AUTOSAR XML (schema 4-0-3)
standard types defined: Boolean, UInt16, UInt8
package /AUTOSAR_Platform/DataConstrs
  range DC_Boolean: raw 0..1
  range DC_UInt16: raw 0..65535
  range DC_UInt8: raw 0..255
package /PATAC/MSM/ComponentTypes
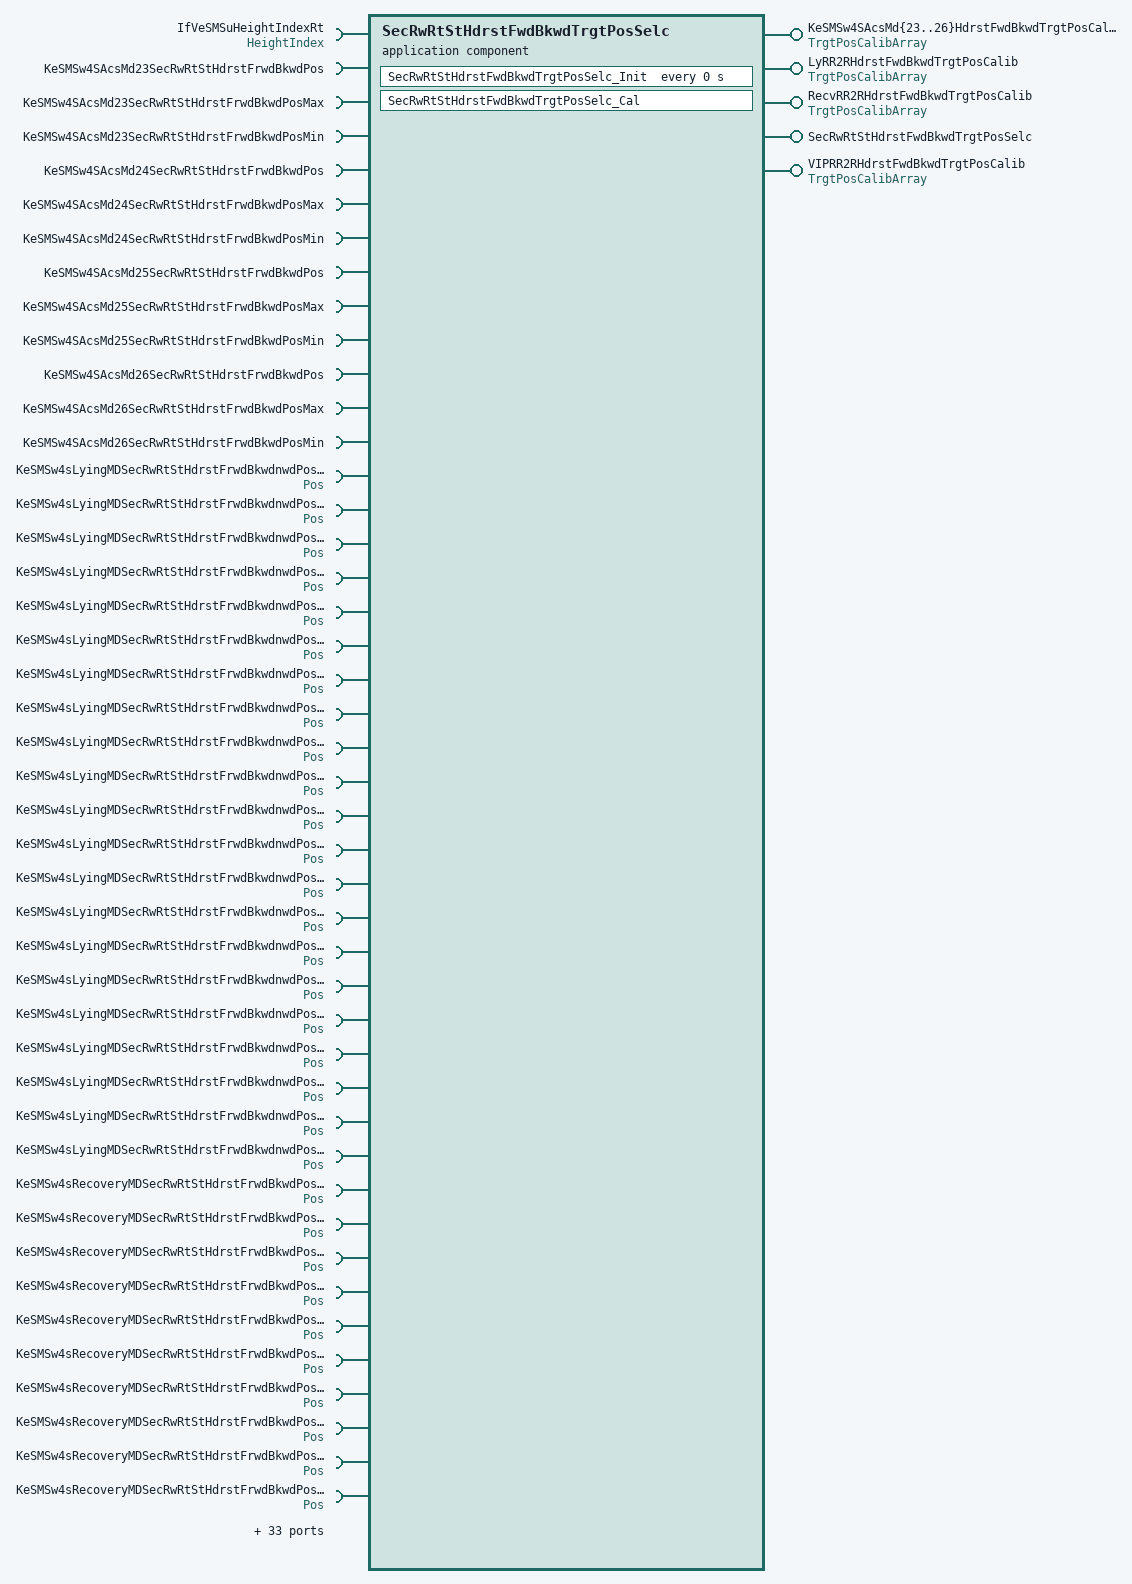
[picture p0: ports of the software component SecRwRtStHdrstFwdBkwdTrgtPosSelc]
  application sw component type SecRwRtStHdrstFwdBkwdTrgtPosSelc
    8 x provide port:
      KeSMSw4SAcsMd{23..26}HdrstFwdBkwdTrgtPosCalib: nonqueued-sender-com-spec{data-element=TrgtPosArray, init-value=[4095, 4095, 4095]}, provided-interface=TrgtPosCalibArray
      LyRR2RHdrstFwdBkwdTrgtPosCalib: nonqueued-sender-com-spec{data-element=TrgtPosArray, init-value=[4095, 4095, 4095]}, provided-interface=TrgtPosCalibArray
      RecvRR2RHdrstFwdBkwdTrgtPosCalib: nonqueued-sender-com-spec{data-element=TrgtPosArray, init-value=[4095, 4095, 4095]}, provided-interface=TrgtPosCalibArray
      SecRwRtStHdrstFwdBkwdTrgtPosSelc: server-com-spec{operation=Cal, queue-length=1}, provided-interface=SecRwRtStHdrstFwdBkwdTrgtPosSelc
      VIPRR2RHdrstFwdBkwdTrgtPosCalib: nonqueued-sender-com-spec{data-element=TrgtPosArray, init-value=[4095, 4095, 4095]}, provided-interface=TrgtPosCalibArray
    77 x require port:
      IfVeSMSuHeightIndexRt: nonqueued-receiver-com-spec{data-element=Val, filter=data-filter-type=ALWAYS, init-value=0}, required-interface=HeightIndex
      KeSMSw4SAcsMd23SecRwRtStHdrstFrwdBkwdPos: parameter-require-com-spec{init-value=0, parameter=KeSMSw4SAcsMd23SecRwRtStHdrstFrwdBkwdPos/Val}, required-interface=KeSMSw4SAcsMd23SecRwRtStHdrstFrwdBkwdPos
      KeSMSw4SAcsMd23SecRwRtStHdrstFrwdBkwdPosMax: parameter-require-com-spec{init-value=0, parameter=KeSMSw4SAcsMd23SecRwRtStHdrstFrwdBkwdPosMax/Val}, required-interface=KeSMSw4SAcsMd23SecRwRtStHdrstFrwdBkwdPosMax
      KeSMSw4SAcsMd23SecRwRtStHdrstFrwdBkwdPosMin: parameter-require-com-spec{init-value=0, parameter=KeSMSw4SAcsMd23SecRwRtStHdrstFrwdBkwdPosMin/Val}, required-interface=KeSMSw4SAcsMd23SecRwRtStHdrstFrwdBkwdPosMin
      KeSMSw4SAcsMd24SecRwRtStHdrstFrwdBkwdPos: parameter-require-com-spec{init-value=0, parameter=KeSMSw4SAcsMd24SecRwRtStHdrstFrwdBkwdPos/Val}, required-interface=KeSMSw4SAcsMd24SecRwRtStHdrstFrwdBkwdPos
      KeSMSw4SAcsMd24SecRwRtStHdrstFrwdBkwdPosMax: parameter-require-com-spec{init-value=0, parameter=KeSMSw4SAcsMd24SecRwRtStHdrstFrwdBkwdPosMax/Val}, required-interface=KeSMSw4SAcsMd24SecRwRtStHdrstFrwdBkwdPosMax
      KeSMSw4SAcsMd24SecRwRtStHdrstFrwdBkwdPosMin: parameter-require-com-spec{init-value=0, parameter=KeSMSw4SAcsMd24SecRwRtStHdrstFrwdBkwdPosMin/Val}, required-interface=KeSMSw4SAcsMd24SecRwRtStHdrstFrwdBkwdPosMin
      KeSMSw4SAcsMd25SecRwRtStHdrstFrwdBkwdPos: parameter-require-com-spec{init-value=0, parameter=KeSMSw4SAcsMd25SecRwRtStHdrstFrwdBkwdPos/Val}, required-interface=KeSMSw4SAcsMd25SecRwRtStHdrstFrwdBkwdPos
      KeSMSw4SAcsMd25SecRwRtStHdrstFrwdBkwdPosMax: parameter-require-com-spec{init-value=0, parameter=KeSMSw4SAcsMd25SecRwRtStHdrstFrwdBkwdPosMax/Val}, required-interface=KeSMSw4SAcsMd25SecRwRtStHdrstFrwdBkwdPosMax
      KeSMSw4SAcsMd25SecRwRtStHdrstFrwdBkwdPosMin: parameter-require-com-spec{init-value=0, parameter=KeSMSw4SAcsMd25SecRwRtStHdrstFrwdBkwdPosMin/Val}, required-interface=KeSMSw4SAcsMd25SecRwRtStHdrstFrwdBkwdPosMin
      KeSMSw4SAcsMd26SecRwRtStHdrstFrwdBkwdPos: parameter-require-com-spec{init-value=0, parameter=KeSMSw4SAcsMd26SecRwRtStHdrstFrwdBkwdPos/Val}, required-interface=KeSMSw4SAcsMd26SecRwRtStHdrstFrwdBkwdPos
      KeSMSw4SAcsMd26SecRwRtStHdrstFrwdBkwdPosMax: parameter-require-com-spec{init-value=0, parameter=KeSMSw4SAcsMd26SecRwRtStHdrstFrwdBkwdPosMax/Val}, required-interface=KeSMSw4SAcsMd26SecRwRtStHdrstFrwdBkwdPosMax
      KeSMSw4SAcsMd26SecRwRtStHdrstFrwdBkwdPosMin: parameter-require-com-spec{init-value=0, parameter=KeSMSw4SAcsMd26SecRwRtStHdrstFrwdBkwdPosMin/Val}, required-interface=KeSMSw4SAcsMd26SecRwRtStHdrstFrwdBkwdPosMin
      KeSMSw4sLyingMDSecRwRtStHdrstFrwdBkwdnwdPos_160: parameter-require-com-spec{init-value=0, parameter=Pos/Val}, required-interface=Pos
      KeSMSw4sLyingMDSecRwRtStHdrstFrwdBkwdnwdPos_165: parameter-require-com-spec{init-value=0, parameter=Pos/Val}, required-interface=Pos
      KeSMSw4sLyingMDSecRwRtStHdrstFrwdBkwdnwdPos_170: parameter-require-com-spec{init-value=0, parameter=Pos/Val}, required-interface=Pos
      KeSMSw4sLyingMDSecRwRtStHdrstFrwdBkwdnwdPos_175: parameter-require-com-spec{init-value=0, parameter=Pos/Val}, required-interface=Pos
      KeSMSw4sLyingMDSecRwRtStHdrstFrwdBkwdnwdPos_180: parameter-require-com-spec{init-value=0, parameter=Pos/Val}, required-interface=Pos
      KeSMSw4sLyingMDSecRwRtStHdrstFrwdBkwdnwdPos_Below160: parameter-require-com-spec{init-value=0, parameter=Pos/Val}, required-interface=Pos
      KeSMSw4sLyingMDSecRwRtStHdrstFrwdBkwdnwdPos_Over180: parameter-require-com-spec{init-value=0, parameter=Pos/Val}, required-interface=Pos
      KeSMSw4sLyingMDSecRwRtStHdrstFrwdBkwdnwdPosMax_160: parameter-require-com-spec{init-value=0, parameter=Pos/Val}, required-interface=Pos
      KeSMSw4sLyingMDSecRwRtStHdrstFrwdBkwdnwdPosMax_165: parameter-require-com-spec{init-value=0, parameter=Pos/Val}, required-interface=Pos
      KeSMSw4sLyingMDSecRwRtStHdrstFrwdBkwdnwdPosMax_170: parameter-require-com-spec{init-value=0, parameter=Pos/Val}, required-interface=Pos
      KeSMSw4sLyingMDSecRwRtStHdrstFrwdBkwdnwdPosMax_175: parameter-require-com-spec{init-value=0, parameter=Pos/Val}, required-interface=Pos
      KeSMSw4sLyingMDSecRwRtStHdrstFrwdBkwdnwdPosMax_180: parameter-require-com-spec{init-value=0, parameter=Pos/Val}, required-interface=Pos
      KeSMSw4sLyingMDSecRwRtStHdrstFrwdBkwdnwdPosMax_Below160: parameter-require-com-spec{init-value=0, parameter=Pos/Val}, required-interface=Pos
      KeSMSw4sLyingMDSecRwRtStHdrstFrwdBkwdnwdPosMax_Over180: parameter-require-com-spec{init-value=0, parameter=Pos/Val}, required-interface=Pos
      KeSMSw4sLyingMDSecRwRtStHdrstFrwdBkwdnwdPosMin_160: parameter-require-com-spec{init-value=0, parameter=Pos/Val}, required-interface=Pos
      KeSMSw4sLyingMDSecRwRtStHdrstFrwdBkwdnwdPosMin_165: parameter-require-com-spec{init-value=0, parameter=Pos/Val}, required-interface=Pos
      KeSMSw4sLyingMDSecRwRtStHdrstFrwdBkwdnwdPosMin_170: parameter-require-com-spec{init-value=0, parameter=Pos/Val}, required-interface=Pos
      KeSMSw4sLyingMDSecRwRtStHdrstFrwdBkwdnwdPosMin_175: parameter-require-com-spec{init-value=0, parameter=Pos/Val}, required-interface=Pos
      KeSMSw4sLyingMDSecRwRtStHdrstFrwdBkwdnwdPosMin_180: parameter-require-com-spec{init-value=0, parameter=Pos/Val}, required-interface=Pos
      KeSMSw4sLyingMDSecRwRtStHdrstFrwdBkwdnwdPosMin_Below160: parameter-require-com-spec{init-value=0, parameter=Pos/Val}, required-interface=Pos
      KeSMSw4sLyingMDSecRwRtStHdrstFrwdBkwdnwdPosMin_Over180: parameter-require-com-spec{init-value=0, parameter=Pos/Val}, required-interface=Pos
      KeSMSw4sRecoveryMDSecRwRtStHdrstFrwdBkwdPos_160: parameter-require-com-spec{init-value=0, parameter=Pos/Val}, required-interface=Pos
      KeSMSw4sRecoveryMDSecRwRtStHdrstFrwdBkwdPos_165: parameter-require-com-spec{init-value=0, parameter=Pos/Val}, required-interface=Pos
      KeSMSw4sRecoveryMDSecRwRtStHdrstFrwdBkwdPos_170: parameter-require-com-spec{init-value=0, parameter=Pos/Val}, required-interface=Pos
      KeSMSw4sRecoveryMDSecRwRtStHdrstFrwdBkwdPos_175: parameter-require-com-spec{init-value=0, parameter=Pos/Val}, required-interface=Pos
      KeSMSw4sRecoveryMDSecRwRtStHdrstFrwdBkwdPos_180: parameter-require-com-spec{init-value=0, parameter=Pos/Val}, required-interface=Pos
      KeSMSw4sRecoveryMDSecRwRtStHdrstFrwdBkwdPos_Below160: parameter-require-com-spec{init-value=0, parameter=Pos/Val}, required-interface=Pos
      KeSMSw4sRecoveryMDSecRwRtStHdrstFrwdBkwdPos_Over180: parameter-require-com-spec{init-value=0, parameter=Pos/Val}, required-interface=Pos
      KeSMSw4sRecoveryMDSecRwRtStHdrstFrwdBkwdPosMax_160: parameter-require-com-spec{init-value=0, parameter=Pos/Val}, required-interface=Pos
      KeSMSw4sRecoveryMDSecRwRtStHdrstFrwdBkwdPosMax_165: parameter-require-com-spec{init-value=0, parameter=Pos/Val}, required-interface=Pos
      KeSMSw4sRecoveryMDSecRwRtStHdrstFrwdBkwdPosMax_170: parameter-require-com-spec{init-value=0, parameter=Pos/Val}, required-interface=Pos
      KeSMSw4sRecoveryMDSecRwRtStHdrstFrwdBkwdPosMax_175: parameter-require-com-spec{init-value=0, parameter=Pos/Val}, required-interface=Pos
      KeSMSw4sRecoveryMDSecRwRtStHdrstFrwdBkwdPosMax_180: parameter-require-com-spec{init-value=0, parameter=Pos/Val}, required-interface=Pos
      KeSMSw4sRecoveryMDSecRwRtStHdrstFrwdBkwdPosMax_Below160: parameter-require-com-spec{init-value=0, parameter=Pos/Val}, required-interface=Pos
      KeSMSw4sRecoveryMDSecRwRtStHdrstFrwdBkwdPosMax_Over180: parameter-require-com-spec{init-value=0, parameter=Pos/Val}, required-interface=Pos
      KeSMSw4sRecoveryMDSecRwRtStHdrstFrwdBkwdPosMin_160: parameter-require-com-spec{init-value=0, parameter=Pos/Val}, required-interface=Pos
      KeSMSw4sRecoveryMDSecRwRtStHdrstFrwdBkwdPosMin_165: parameter-require-com-spec{init-value=0, parameter=Pos/Val}, required-interface=Pos
      KeSMSw4sRecoveryMDSecRwRtStHdrstFrwdBkwdPosMin_170: parameter-require-com-spec{init-value=0, parameter=Pos/Val}, required-interface=Pos
      KeSMSw4sRecoveryMDSecRwRtStHdrstFrwdBkwdPosMin_175: parameter-require-com-spec{init-value=0, parameter=Pos/Val}, required-interface=Pos
      KeSMSw4sRecoveryMDSecRwRtStHdrstFrwdBkwdPosMin_180: parameter-require-com-spec{init-value=0, parameter=Pos/Val}, required-interface=Pos
      KeSMSw4sRecoveryMDSecRwRtStHdrstFrwdBkwdPosMin_Below160: parameter-require-com-spec{init-value=0, parameter=Pos/Val}, required-interface=Pos
      KeSMSw4sRecoveryMDSecRwRtStHdrstFrwdBkwdPosMin_Over180: parameter-require-com-spec{init-value=0, parameter=Pos/Val}, required-interface=Pos
      KeSMSw4sVIPMDSecRwRtStHdrstFrwdBkwdPos_160: parameter-require-com-spec{init-value=0, parameter=Pos/Val}, required-interface=Pos
      KeSMSw4sVIPMDSecRwRtStHdrstFrwdBkwdPos_165: parameter-require-com-spec{init-value=0, parameter=Pos/Val}, required-interface=Pos
      KeSMSw4sVIPMDSecRwRtStHdrstFrwdBkwdPos_170: parameter-require-com-spec{init-value=0, parameter=Pos/Val}, required-interface=Pos
      KeSMSw4sVIPMDSecRwRtStHdrstFrwdBkwdPos_175: parameter-require-com-spec{init-value=0, parameter=Pos/Val}, required-interface=Pos
      KeSMSw4sVIPMDSecRwRtStHdrstFrwdBkwdPos_180: parameter-require-com-spec{init-value=0, parameter=Pos/Val}, required-interface=Pos
      KeSMSw4sVIPMDSecRwRtStHdrstFrwdBkwdPos_Below160: parameter-require-com-spec{init-value=0, parameter=Pos/Val}, required-interface=Pos
      KeSMSw4sVIPMDSecRwRtStHdrstFrwdBkwdPos_Over180: parameter-require-com-spec{init-value=0, parameter=Pos/Val}, required-interface=Pos
      KeSMSw4sVIPMDSecRwRtStHdrstFrwdBkwdPosMax_160: parameter-require-com-spec{init-value=0, parameter=Pos/Val}, required-interface=Pos
      KeSMSw4sVIPMDSecRwRtStHdrstFrwdBkwdPosMax_165: parameter-require-com-spec{init-value=0, parameter=Pos/Val}, required-interface=Pos
      KeSMSw4sVIPMDSecRwRtStHdrstFrwdBkwdPosMax_170: parameter-require-com-spec{init-value=0, parameter=Pos/Val}, required-interface=Pos
      KeSMSw4sVIPMDSecRwRtStHdrstFrwdBkwdPosMax_175: parameter-require-com-spec{init-value=0, parameter=Pos/Val}, required-interface=Pos
      KeSMSw4sVIPMDSecRwRtStHdrstFrwdBkwdPosMax_180: parameter-require-com-spec{init-value=0, parameter=Pos/Val}, required-interface=Pos
      KeSMSw4sVIPMDSecRwRtStHdrstFrwdBkwdPosMax_Below160: parameter-require-com-spec{init-value=0, parameter=Pos/Val}, required-interface=Pos
      KeSMSw4sVIPMDSecRwRtStHdrstFrwdBkwdPosMax_Over180: parameter-require-com-spec{init-value=0, parameter=Pos/Val}, required-interface=Pos
      KeSMSw4sVIPMDSecRwRtStHdrstFrwdBkwdPosMin_160: parameter-require-com-spec{init-value=0, parameter=Pos/Val}, required-interface=Pos
      KeSMSw4sVIPMDSecRwRtStHdrstFrwdBkwdPosMin_165: parameter-require-com-spec{init-value=0, parameter=Pos/Val}, required-interface=Pos
      KeSMSw4sVIPMDSecRwRtStHdrstFrwdBkwdPosMin_170: parameter-require-com-spec{init-value=0, parameter=Pos/Val}, required-interface=Pos
      KeSMSw4sVIPMDSecRwRtStHdrstFrwdBkwdPosMin_175: parameter-require-com-spec{init-value=0, parameter=Pos/Val}, required-interface=Pos
      KeSMSw4sVIPMDSecRwRtStHdrstFrwdBkwdPosMin_180: parameter-require-com-spec{init-value=0, parameter=Pos/Val}, required-interface=Pos
      KeSMSw4sVIPMDSecRwRtStHdrstFrwdBkwdPosMin_Below160: parameter-require-com-spec{init-value=0, parameter=Pos/Val}, required-interface=Pos
      KeSMSw4sVIPMDSecRwRtStHdrstFrwdBkwdPosMin_Over180: parameter-require-com-spec{init-value=0, parameter=Pos/Val}, required-interface=Pos
      StNumFlg: required-interface=StNumFlg
        required-com-specs:
          data-element=Is4s, filter=data-filter-type=ALWAYS, init-value=0
          data-element=Is6s, filter=data-filter-type=ALWAYS, init-value=0
          data-element=Is6s7s, filter=data-filter-type=ALWAYS, init-value=0
          data-element=Is7s, filter=data-filter-type=ALWAYS, init-value=0
    behavior SecRwRtStHdrstFwdBkwdTrgtPosSelc_InternalBehavior
      operation invoked event OIT_SecRwRtStHdrstFwdBkwdTrgtPosSelc_Cal_SecRwRtStHdrstFwdBkwdTrgtPosSelc_Cal: start-on-event=SecRwRtStHdrstFwdBkwdTrgtPosSelc_Cal, operation=SecRwRtStHdrstFwdBkwdTrgtPosSelc.Cal
      timing event SecRwRtStHdrstFwdBkwdTrgtPosSelc_InitEvent: start-on-event=SecRwRtStHdrstFwdBkwdTrgtPosSelc_Init, period=0
      runnable SecRwRtStHdrstFwdBkwdTrgtPosSelc_Cal
        data-receive-point-by-arguments:
          5 x access:
            REC_IfVeSMSuHeightIndexRt_Val: accessed-variable=IfVeSMSuHeightIndexRt.Val
            REC_StNumFlg_Is4s: accessed-variable=StNumFlg.Is4s
            REC_StNumFlg_Is6s: accessed-variable=StNumFlg.Is6s
            REC_StNumFlg_Is6s7s: accessed-variable=StNumFlg.Is6s7s
            REC_StNumFlg_Is7s: accessed-variable=StNumFlg.Is7s
        data-send-points:
          7 x access:
            SEND_KeSMSw4SAcsMd{23..26}HdrstFwdBkwdTrgtPosCalib_TrgtPosArray: accessed-variable=KeSMSw4SAcsMd{23..26}HdrstFwdBkwdTrgtPosCalib.TrgtPosArray
            SEND_LyRR2RHdrstFwdBkwdTrgtPosCalib_TrgtPosArray: accessed-variable=LyRR2RHdrstFwdBkwdTrgtPosCalib.TrgtPosArray
            SEND_RecvRR2RHdrstFwdBkwdTrgtPosCalib_TrgtPosArray: accessed-variable=RecvRR2RHdrstFwdBkwdTrgtPosCalib.TrgtPosArray
            SEND_VIPRR2RHdrstFwdBkwdTrgtPosCalib_TrgtPosArray: accessed-variable=VIPRR2RHdrstFwdBkwdTrgtPosCalib.TrgtPosArray
        75 x parameter access:
          PA_KeSMSw4SAcsMd23SecRwRtStHdrstFrwdBkwdPos_Val: accessed-parameter=KeSMSw4SAcsMd23SecRwRtStHdrstFrwdBkwdPos.Val
          PA_KeSMSw4SAcsMd23SecRwRtStHdrstFrwdBkwdPosMax_Val: accessed-parameter=KeSMSw4SAcsMd23SecRwRtStHdrstFrwdBkwdPosMax.Val
          PA_KeSMSw4SAcsMd23SecRwRtStHdrstFrwdBkwdPosMin_Val: accessed-parameter=KeSMSw4SAcsMd23SecRwRtStHdrstFrwdBkwdPosMin.Val
          PA_KeSMSw4SAcsMd24SecRwRtStHdrstFrwdBkwdPos_Val: accessed-parameter=KeSMSw4SAcsMd24SecRwRtStHdrstFrwdBkwdPos.Val
          PA_KeSMSw4SAcsMd24SecRwRtStHdrstFrwdBkwdPosMax_Val: accessed-parameter=KeSMSw4SAcsMd24SecRwRtStHdrstFrwdBkwdPosMax.Val
          PA_KeSMSw4SAcsMd24SecRwRtStHdrstFrwdBkwdPosMin_Val: accessed-parameter=KeSMSw4SAcsMd24SecRwRtStHdrstFrwdBkwdPosMin.Val
          PA_KeSMSw4SAcsMd25SecRwRtStHdrstFrwdBkwdPos_Val: accessed-parameter=KeSMSw4SAcsMd25SecRwRtStHdrstFrwdBkwdPos.Val
          PA_KeSMSw4SAcsMd25SecRwRtStHdrstFrwdBkwdPosMax_Val: accessed-parameter=KeSMSw4SAcsMd25SecRwRtStHdrstFrwdBkwdPosMax.Val
          PA_KeSMSw4SAcsMd25SecRwRtStHdrstFrwdBkwdPosMin_Val: accessed-parameter=KeSMSw4SAcsMd25SecRwRtStHdrstFrwdBkwdPosMin.Val
          PA_KeSMSw4SAcsMd26SecRwRtStHdrstFrwdBkwdPos_Val: accessed-parameter=KeSMSw4SAcsMd26SecRwRtStHdrstFrwdBkwdPos.Val
          PA_KeSMSw4SAcsMd26SecRwRtStHdrstFrwdBkwdPosMax_Val: accessed-parameter=KeSMSw4SAcsMd26SecRwRtStHdrstFrwdBkwdPosMax.Val
          PA_KeSMSw4SAcsMd26SecRwRtStHdrstFrwdBkwdPosMin_Val: accessed-parameter=KeSMSw4SAcsMd26SecRwRtStHdrstFrwdBkwdPosMin.Val
          PA_KeSMSw4sLyingMDSecRwRtStHdrstFrwdBkwdnwdPos_160_Val: accessed-parameter=KeSMSw4sLyingMDSecRwRtStHdrstFrwdBkwdnwdPos_160.Val
          PA_KeSMSw4sLyingMDSecRwRtStHdrstFrwdBkwdnwdPos_165_Val: accessed-parameter=KeSMSw4sLyingMDSecRwRtStHdrstFrwdBkwdnwdPos_165.Val
          PA_KeSMSw4sLyingMDSecRwRtStHdrstFrwdBkwdnwdPos_170_Val: accessed-parameter=KeSMSw4sLyingMDSecRwRtStHdrstFrwdBkwdnwdPos_170.Val
          PA_KeSMSw4sLyingMDSecRwRtStHdrstFrwdBkwdnwdPos_175_Val: accessed-parameter=KeSMSw4sLyingMDSecRwRtStHdrstFrwdBkwdnwdPos_175.Val
          PA_KeSMSw4sLyingMDSecRwRtStHdrstFrwdBkwdnwdPos_180_Val: accessed-parameter=KeSMSw4sLyingMDSecRwRtStHdrstFrwdBkwdnwdPos_180.Val
          PA_KeSMSw4sLyingMDSecRwRtStHdrstFrwdBkwdnwdPos_Below160_Val: accessed-parameter=KeSMSw4sLyingMDSecRwRtStHdrstFrwdBkwdnwdPos_Below160.Val
          PA_KeSMSw4sLyingMDSecRwRtStHdrstFrwdBkwdnwdPos_Over180_Val: accessed-parameter=KeSMSw4sLyingMDSecRwRtStHdrstFrwdBkwdnwdPos_Over180.Val
          PA_KeSMSw4sLyingMDSecRwRtStHdrstFrwdBkwdnwdPosMax_160_Val: accessed-parameter=KeSMSw4sLyingMDSecRwRtStHdrstFrwdBkwdnwdPosMax_160.Val
          PA_KeSMSw4sLyingMDSecRwRtStHdrstFrwdBkwdnwdPosMax_165_Val: accessed-parameter=KeSMSw4sLyingMDSecRwRtStHdrstFrwdBkwdnwdPosMax_165.Val
          PA_KeSMSw4sLyingMDSecRwRtStHdrstFrwdBkwdnwdPosMax_170_Val: accessed-parameter=KeSMSw4sLyingMDSecRwRtStHdrstFrwdBkwdnwdPosMax_170.Val
          PA_KeSMSw4sLyingMDSecRwRtStHdrstFrwdBkwdnwdPosMax_175_Val: accessed-parameter=KeSMSw4sLyingMDSecRwRtStHdrstFrwdBkwdnwdPosMax_175.Val
          PA_KeSMSw4sLyingMDSecRwRtStHdrstFrwdBkwdnwdPosMax_180_Val: accessed-parameter=KeSMSw4sLyingMDSecRwRtStHdrstFrwdBkwdnwdPosMax_180.Val
          PA_KeSMSw4sLyingMDSecRwRtStHdrstFrwdBkwdnwdPosMax_Below160_Val: accessed-parameter=KeSMSw4sLyingMDSecRwRtStHdrstFrwdBkwdnwdPosMax_Below160.Val
          PA_KeSMSw4sLyingMDSecRwRtStHdrstFrwdBkwdnwdPosMax_Over180_Val: accessed-parameter=KeSMSw4sLyingMDSecRwRtStHdrstFrwdBkwdnwdPosMax_Over180.Val
          PA_KeSMSw4sLyingMDSecRwRtStHdrstFrwdBkwdnwdPosMin_160_Val: accessed-parameter=KeSMSw4sLyingMDSecRwRtStHdrstFrwdBkwdnwdPosMin_160.Val
          PA_KeSMSw4sLyingMDSecRwRtStHdrstFrwdBkwdnwdPosMin_165_Val: accessed-parameter=KeSMSw4sLyingMDSecRwRtStHdrstFrwdBkwdnwdPosMin_165.Val
          PA_KeSMSw4sLyingMDSecRwRtStHdrstFrwdBkwdnwdPosMin_170_Val: accessed-parameter=KeSMSw4sLyingMDSecRwRtStHdrstFrwdBkwdnwdPosMin_170.Val
          PA_KeSMSw4sLyingMDSecRwRtStHdrstFrwdBkwdnwdPosMin_175_Val: accessed-parameter=KeSMSw4sLyingMDSecRwRtStHdrstFrwdBkwdnwdPosMin_175.Val
          PA_KeSMSw4sLyingMDSecRwRtStHdrstFrwdBkwdnwdPosMin_180_Val: accessed-parameter=KeSMSw4sLyingMDSecRwRtStHdrstFrwdBkwdnwdPosMin_180.Val
          PA_KeSMSw4sLyingMDSecRwRtStHdrstFrwdBkwdnwdPosMin_Below160_Val: accessed-parameter=KeSMSw4sLyingMDSecRwRtStHdrstFrwdBkwdnwdPosMin_Below160.Val
          PA_KeSMSw4sLyingMDSecRwRtStHdrstFrwdBkwdnwdPosMin_Over180_Val: accessed-parameter=KeSMSw4sLyingMDSecRwRtStHdrstFrwdBkwdnwdPosMin_Over180.Val
          PA_KeSMSw4sRecoveryMDSecRwRtStHdrstFrwdBkwdPos_160_Val: accessed-parameter=KeSMSw4sRecoveryMDSecRwRtStHdrstFrwdBkwdPos_160.Val
          PA_KeSMSw4sRecoveryMDSecRwRtStHdrstFrwdBkwdPos_165_Val: accessed-parameter=KeSMSw4sRecoveryMDSecRwRtStHdrstFrwdBkwdPos_165.Val
          PA_KeSMSw4sRecoveryMDSecRwRtStHdrstFrwdBkwdPos_170_Val: accessed-parameter=KeSMSw4sRecoveryMDSecRwRtStHdrstFrwdBkwdPos_170.Val
          PA_KeSMSw4sRecoveryMDSecRwRtStHdrstFrwdBkwdPos_175_Val: accessed-parameter=KeSMSw4sRecoveryMDSecRwRtStHdrstFrwdBkwdPos_175.Val
          PA_KeSMSw4sRecoveryMDSecRwRtStHdrstFrwdBkwdPos_180_Val: accessed-parameter=KeSMSw4sRecoveryMDSecRwRtStHdrstFrwdBkwdPos_180.Val
          PA_KeSMSw4sRecoveryMDSecRwRtStHdrstFrwdBkwdPos_Below160_Val: accessed-parameter=KeSMSw4sRecoveryMDSecRwRtStHdrstFrwdBkwdPos_Below160.Val
          PA_KeSMSw4sRecoveryMDSecRwRtStHdrstFrwdBkwdPos_Over180_Val: accessed-parameter=KeSMSw4sRecoveryMDSecRwRtStHdrstFrwdBkwdPos_Over180.Val
          PA_KeSMSw4sRecoveryMDSecRwRtStHdrstFrwdBkwdPosMax_160_Val: accessed-parameter=KeSMSw4sRecoveryMDSecRwRtStHdrstFrwdBkwdPosMax_160.Val
          PA_KeSMSw4sRecoveryMDSecRwRtStHdrstFrwdBkwdPosMax_165_Val: accessed-parameter=KeSMSw4sRecoveryMDSecRwRtStHdrstFrwdBkwdPosMax_165.Val
          PA_KeSMSw4sRecoveryMDSecRwRtStHdrstFrwdBkwdPosMax_170_Val: accessed-parameter=KeSMSw4sRecoveryMDSecRwRtStHdrstFrwdBkwdPosMax_170.Val
          PA_KeSMSw4sRecoveryMDSecRwRtStHdrstFrwdBkwdPosMax_175_Val: accessed-parameter=KeSMSw4sRecoveryMDSecRwRtStHdrstFrwdBkwdPosMax_175.Val
          PA_KeSMSw4sRecoveryMDSecRwRtStHdrstFrwdBkwdPosMax_180_Val: accessed-parameter=KeSMSw4sRecoveryMDSecRwRtStHdrstFrwdBkwdPosMax_180.Val
          PA_KeSMSw4sRecoveryMDSecRwRtStHdrstFrwdBkwdPosMax_Below160_Val: accessed-parameter=KeSMSw4sRecoveryMDSecRwRtStHdrstFrwdBkwdPosMax_Below160.Val
          PA_KeSMSw4sRecoveryMDSecRwRtStHdrstFrwdBkwdPosMax_Over180_Val: accessed-parameter=KeSMSw4sRecoveryMDSecRwRtStHdrstFrwdBkwdPosMax_Over180.Val
          PA_KeSMSw4sRecoveryMDSecRwRtStHdrstFrwdBkwdPosMin_160_Val: accessed-parameter=KeSMSw4sRecoveryMDSecRwRtStHdrstFrwdBkwdPosMin_160.Val
          PA_KeSMSw4sRecoveryMDSecRwRtStHdrstFrwdBkwdPosMin_165_Val: accessed-parameter=KeSMSw4sRecoveryMDSecRwRtStHdrstFrwdBkwdPosMin_165.Val
          PA_KeSMSw4sRecoveryMDSecRwRtStHdrstFrwdBkwdPosMin_170_Val: accessed-parameter=KeSMSw4sRecoveryMDSecRwRtStHdrstFrwdBkwdPosMin_170.Val
          PA_KeSMSw4sRecoveryMDSecRwRtStHdrstFrwdBkwdPosMin_175_Val: accessed-parameter=KeSMSw4sRecoveryMDSecRwRtStHdrstFrwdBkwdPosMin_175.Val
          PA_KeSMSw4sRecoveryMDSecRwRtStHdrstFrwdBkwdPosMin_180_Val: accessed-parameter=KeSMSw4sRecoveryMDSecRwRtStHdrstFrwdBkwdPosMin_180.Val
          PA_KeSMSw4sRecoveryMDSecRwRtStHdrstFrwdBkwdPosMin_Below160_Val: accessed-parameter=KeSMSw4sRecoveryMDSecRwRtStHdrstFrwdBkwdPosMin_Below160.Val
          PA_KeSMSw4sRecoveryMDSecRwRtStHdrstFrwdBkwdPosMin_Over180_Val: accessed-parameter=KeSMSw4sRecoveryMDSecRwRtStHdrstFrwdBkwdPosMin_Over180.Val
          PA_KeSMSw4sVIPMDSecRwRtStHdrstFrwdBkwdPos_160_Val: accessed-parameter=KeSMSw4sVIPMDSecRwRtStHdrstFrwdBkwdPos_160.Val
          PA_KeSMSw4sVIPMDSecRwRtStHdrstFrwdBkwdPos_165_Val: accessed-parameter=KeSMSw4sVIPMDSecRwRtStHdrstFrwdBkwdPos_165.Val
          PA_KeSMSw4sVIPMDSecRwRtStHdrstFrwdBkwdPos_170_Val: accessed-parameter=KeSMSw4sVIPMDSecRwRtStHdrstFrwdBkwdPos_170.Val
          PA_KeSMSw4sVIPMDSecRwRtStHdrstFrwdBkwdPos_175_Val: accessed-parameter=KeSMSw4sVIPMDSecRwRtStHdrstFrwdBkwdPos_175.Val
          PA_KeSMSw4sVIPMDSecRwRtStHdrstFrwdBkwdPos_180_Val: accessed-parameter=KeSMSw4sVIPMDSecRwRtStHdrstFrwdBkwdPos_180.Val
          PA_KeSMSw4sVIPMDSecRwRtStHdrstFrwdBkwdPos_Below160_Val: accessed-parameter=KeSMSw4sVIPMDSecRwRtStHdrstFrwdBkwdPos_Below160.Val
          PA_KeSMSw4sVIPMDSecRwRtStHdrstFrwdBkwdPos_Over180_Val: accessed-parameter=KeSMSw4sVIPMDSecRwRtStHdrstFrwdBkwdPos_Over180.Val
          PA_KeSMSw4sVIPMDSecRwRtStHdrstFrwdBkwdPosMax_160_Val: accessed-parameter=KeSMSw4sVIPMDSecRwRtStHdrstFrwdBkwdPosMax_160.Val
          PA_KeSMSw4sVIPMDSecRwRtStHdrstFrwdBkwdPosMax_165_Val: accessed-parameter=KeSMSw4sVIPMDSecRwRtStHdrstFrwdBkwdPosMax_165.Val
          PA_KeSMSw4sVIPMDSecRwRtStHdrstFrwdBkwdPosMax_170_Val: accessed-parameter=KeSMSw4sVIPMDSecRwRtStHdrstFrwdBkwdPosMax_170.Val
          PA_KeSMSw4sVIPMDSecRwRtStHdrstFrwdBkwdPosMax_175_Val: accessed-parameter=KeSMSw4sVIPMDSecRwRtStHdrstFrwdBkwdPosMax_175.Val
          PA_KeSMSw4sVIPMDSecRwRtStHdrstFrwdBkwdPosMax_180_Val: accessed-parameter=KeSMSw4sVIPMDSecRwRtStHdrstFrwdBkwdPosMax_180.Val
          PA_KeSMSw4sVIPMDSecRwRtStHdrstFrwdBkwdPosMax_Below160_Val: accessed-parameter=KeSMSw4sVIPMDSecRwRtStHdrstFrwdBkwdPosMax_Below160.Val
          PA_KeSMSw4sVIPMDSecRwRtStHdrstFrwdBkwdPosMax_Over180_Val: accessed-parameter=KeSMSw4sVIPMDSecRwRtStHdrstFrwdBkwdPosMax_Over180.Val
          PA_KeSMSw4sVIPMDSecRwRtStHdrstFrwdBkwdPosMin_160_Val: accessed-parameter=KeSMSw4sVIPMDSecRwRtStHdrstFrwdBkwdPosMin_160.Val
          PA_KeSMSw4sVIPMDSecRwRtStHdrstFrwdBkwdPosMin_165_Val: accessed-parameter=KeSMSw4sVIPMDSecRwRtStHdrstFrwdBkwdPosMin_165.Val
          PA_KeSMSw4sVIPMDSecRwRtStHdrstFrwdBkwdPosMin_170_Val: accessed-parameter=KeSMSw4sVIPMDSecRwRtStHdrstFrwdBkwdPosMin_170.Val
          PA_KeSMSw4sVIPMDSecRwRtStHdrstFrwdBkwdPosMin_175_Val: accessed-parameter=KeSMSw4sVIPMDSecRwRtStHdrstFrwdBkwdPosMin_175.Val
          PA_KeSMSw4sVIPMDSecRwRtStHdrstFrwdBkwdPosMin_180_Val: accessed-parameter=KeSMSw4sVIPMDSecRwRtStHdrstFrwdBkwdPosMin_180.Val
          PA_KeSMSw4sVIPMDSecRwRtStHdrstFrwdBkwdPosMin_Below160_Val: accessed-parameter=KeSMSw4sVIPMDSecRwRtStHdrstFrwdBkwdPosMin_Below160.Val
          PA_KeSMSw4sVIPMDSecRwRtStHdrstFrwdBkwdPosMin_Over180_Val: accessed-parameter=KeSMSw4sVIPMDSecRwRtStHdrstFrwdBkwdPosMin_Over180.Val
      runnable SecRwRtStHdrstFwdBkwdTrgtPosSelc_Init
        75 x parameter access:
          PA_KeSMSw4SAcsMd23SecRwRtStHdrstFrwdBkwdPos_Val: accessed-parameter=KeSMSw4SAcsMd23SecRwRtStHdrstFrwdBkwdPos.Val
          PA_KeSMSw4SAcsMd23SecRwRtStHdrstFrwdBkwdPosMax_Val: accessed-parameter=KeSMSw4SAcsMd23SecRwRtStHdrstFrwdBkwdPosMax.Val
          PA_KeSMSw4SAcsMd23SecRwRtStHdrstFrwdBkwdPosMin_Val: accessed-parameter=KeSMSw4SAcsMd23SecRwRtStHdrstFrwdBkwdPosMin.Val
          PA_KeSMSw4SAcsMd24SecRwRtStHdrstFrwdBkwdPos_Val: accessed-parameter=KeSMSw4SAcsMd24SecRwRtStHdrstFrwdBkwdPos.Val
          PA_KeSMSw4SAcsMd24SecRwRtStHdrstFrwdBkwdPosMax_Val: accessed-parameter=KeSMSw4SAcsMd24SecRwRtStHdrstFrwdBkwdPosMax.Val
          PA_KeSMSw4SAcsMd24SecRwRtStHdrstFrwdBkwdPosMin_Val: accessed-parameter=KeSMSw4SAcsMd24SecRwRtStHdrstFrwdBkwdPosMin.Val
          PA_KeSMSw4SAcsMd25SecRwRtStHdrstFrwdBkwdPos_Val: accessed-parameter=KeSMSw4SAcsMd25SecRwRtStHdrstFrwdBkwdPos.Val
          PA_KeSMSw4SAcsMd25SecRwRtStHdrstFrwdBkwdPosMax_Val: accessed-parameter=KeSMSw4SAcsMd25SecRwRtStHdrstFrwdBkwdPosMax.Val
          PA_KeSMSw4SAcsMd25SecRwRtStHdrstFrwdBkwdPosMin_Val: accessed-parameter=KeSMSw4SAcsMd25SecRwRtStHdrstFrwdBkwdPosMin.Val
          PA_KeSMSw4SAcsMd26SecRwRtStHdrstFrwdBkwdPos_Val: accessed-parameter=KeSMSw4SAcsMd26SecRwRtStHdrstFrwdBkwdPos.Val
          PA_KeSMSw4SAcsMd26SecRwRtStHdrstFrwdBkwdPosMax_Val: accessed-parameter=KeSMSw4SAcsMd26SecRwRtStHdrstFrwdBkwdPosMax.Val
          PA_KeSMSw4SAcsMd26SecRwRtStHdrstFrwdBkwdPosMin_Val: accessed-parameter=KeSMSw4SAcsMd26SecRwRtStHdrstFrwdBkwdPosMin.Val
          PA_KeSMSw4sLyingMDSecRwRtStHdrstFrwdBkwdnwdPos_160_Val: accessed-parameter=KeSMSw4sLyingMDSecRwRtStHdrstFrwdBkwdnwdPos_160.Val
          PA_KeSMSw4sLyingMDSecRwRtStHdrstFrwdBkwdnwdPos_165_Val: accessed-parameter=KeSMSw4sLyingMDSecRwRtStHdrstFrwdBkwdnwdPos_165.Val
          PA_KeSMSw4sLyingMDSecRwRtStHdrstFrwdBkwdnwdPos_170_Val: accessed-parameter=KeSMSw4sLyingMDSecRwRtStHdrstFrwdBkwdnwdPos_170.Val
          PA_KeSMSw4sLyingMDSecRwRtStHdrstFrwdBkwdnwdPos_175_Val: accessed-parameter=KeSMSw4sLyingMDSecRwRtStHdrstFrwdBkwdnwdPos_175.Val
          PA_KeSMSw4sLyingMDSecRwRtStHdrstFrwdBkwdnwdPos_180_Val: accessed-parameter=KeSMSw4sLyingMDSecRwRtStHdrstFrwdBkwdnwdPos_180.Val
          PA_KeSMSw4sLyingMDSecRwRtStHdrstFrwdBkwdnwdPos_Below160_Val: accessed-parameter=KeSMSw4sLyingMDSecRwRtStHdrstFrwdBkwdnwdPos_Below160.Val
          PA_KeSMSw4sLyingMDSecRwRtStHdrstFrwdBkwdnwdPos_Over180_Val: accessed-parameter=KeSMSw4sLyingMDSecRwRtStHdrstFrwdBkwdnwdPos_Over180.Val
          PA_KeSMSw4sLyingMDSecRwRtStHdrstFrwdBkwdnwdPosMax_160_Val: accessed-parameter=KeSMSw4sLyingMDSecRwRtStHdrstFrwdBkwdnwdPosMax_160.Val
          PA_KeSMSw4sLyingMDSecRwRtStHdrstFrwdBkwdnwdPosMax_165_Val: accessed-parameter=KeSMSw4sLyingMDSecRwRtStHdrstFrwdBkwdnwdPosMax_165.Val
          PA_KeSMSw4sLyingMDSecRwRtStHdrstFrwdBkwdnwdPosMax_170_Val: accessed-parameter=KeSMSw4sLyingMDSecRwRtStHdrstFrwdBkwdnwdPosMax_170.Val
          PA_KeSMSw4sLyingMDSecRwRtStHdrstFrwdBkwdnwdPosMax_175_Val: accessed-parameter=KeSMSw4sLyingMDSecRwRtStHdrstFrwdBkwdnwdPosMax_175.Val
          PA_KeSMSw4sLyingMDSecRwRtStHdrstFrwdBkwdnwdPosMax_180_Val: accessed-parameter=KeSMSw4sLyingMDSecRwRtStHdrstFrwdBkwdnwdPosMax_180.Val
          PA_KeSMSw4sLyingMDSecRwRtStHdrstFrwdBkwdnwdPosMax_Below160_Val: accessed-parameter=KeSMSw4sLyingMDSecRwRtStHdrstFrwdBkwdnwdPosMax_Below160.Val
          PA_KeSMSw4sLyingMDSecRwRtStHdrstFrwdBkwdnwdPosMax_Over180_Val: accessed-parameter=KeSMSw4sLyingMDSecRwRtStHdrstFrwdBkwdnwdPosMax_Over180.Val
          PA_KeSMSw4sLyingMDSecRwRtStHdrstFrwdBkwdnwdPosMin_160_Val: accessed-parameter=KeSMSw4sLyingMDSecRwRtStHdrstFrwdBkwdnwdPosMin_160.Val
          PA_KeSMSw4sLyingMDSecRwRtStHdrstFrwdBkwdnwdPosMin_165_Val: accessed-parameter=KeSMSw4sLyingMDSecRwRtStHdrstFrwdBkwdnwdPosMin_165.Val
          PA_KeSMSw4sLyingMDSecRwRtStHdrstFrwdBkwdnwdPosMin_170_Val: accessed-parameter=KeSMSw4sLyingMDSecRwRtStHdrstFrwdBkwdnwdPosMin_170.Val
          PA_KeSMSw4sLyingMDSecRwRtStHdrstFrwdBkwdnwdPosMin_175_Val: accessed-parameter=KeSMSw4sLyingMDSecRwRtStHdrstFrwdBkwdnwdPosMin_175.Val
          PA_KeSMSw4sLyingMDSecRwRtStHdrstFrwdBkwdnwdPosMin_180_Val: accessed-parameter=KeSMSw4sLyingMDSecRwRtStHdrstFrwdBkwdnwdPosMin_180.Val
          PA_KeSMSw4sLyingMDSecRwRtStHdrstFrwdBkwdnwdPosMin_Below160_Val: accessed-parameter=KeSMSw4sLyingMDSecRwRtStHdrstFrwdBkwdnwdPosMin_Below160.Val
          PA_KeSMSw4sLyingMDSecRwRtStHdrstFrwdBkwdnwdPosMin_Over180_Val: accessed-parameter=KeSMSw4sLyingMDSecRwRtStHdrstFrwdBkwdnwdPosMin_Over180.Val
          PA_KeSMSw4sRecoveryMDSecRwRtStHdrstFrwdBkwdPos_160_Val: accessed-parameter=KeSMSw4sRecoveryMDSecRwRtStHdrstFrwdBkwdPos_160.Val
          PA_KeSMSw4sRecoveryMDSecRwRtStHdrstFrwdBkwdPos_165_Val: accessed-parameter=KeSMSw4sRecoveryMDSecRwRtStHdrstFrwdBkwdPos_165.Val
          PA_KeSMSw4sRecoveryMDSecRwRtStHdrstFrwdBkwdPos_170_Val: accessed-parameter=KeSMSw4sRecoveryMDSecRwRtStHdrstFrwdBkwdPos_170.Val
          PA_KeSMSw4sRecoveryMDSecRwRtStHdrstFrwdBkwdPos_175_Val: accessed-parameter=KeSMSw4sRecoveryMDSecRwRtStHdrstFrwdBkwdPos_175.Val
          PA_KeSMSw4sRecoveryMDSecRwRtStHdrstFrwdBkwdPos_180_Val: accessed-parameter=KeSMSw4sRecoveryMDSecRwRtStHdrstFrwdBkwdPos_180.Val
          PA_KeSMSw4sRecoveryMDSecRwRtStHdrstFrwdBkwdPos_Below160_Val: accessed-parameter=KeSMSw4sRecoveryMDSecRwRtStHdrstFrwdBkwdPos_Below160.Val
          PA_KeSMSw4sRecoveryMDSecRwRtStHdrstFrwdBkwdPos_Over180_Val: accessed-parameter=KeSMSw4sRecoveryMDSecRwRtStHdrstFrwdBkwdPos_Over180.Val
          PA_KeSMSw4sRecoveryMDSecRwRtStHdrstFrwdBkwdPosMax_160_Val: accessed-parameter=KeSMSw4sRecoveryMDSecRwRtStHdrstFrwdBkwdPosMax_160.Val
          PA_KeSMSw4sRecoveryMDSecRwRtStHdrstFrwdBkwdPosMax_165_Val: accessed-parameter=KeSMSw4sRecoveryMDSecRwRtStHdrstFrwdBkwdPosMax_165.Val
          PA_KeSMSw4sRecoveryMDSecRwRtStHdrstFrwdBkwdPosMax_170_Val: accessed-parameter=KeSMSw4sRecoveryMDSecRwRtStHdrstFrwdBkwdPosMax_170.Val
          PA_KeSMSw4sRecoveryMDSecRwRtStHdrstFrwdBkwdPosMax_175_Val: accessed-parameter=KeSMSw4sRecoveryMDSecRwRtStHdrstFrwdBkwdPosMax_175.Val
          PA_KeSMSw4sRecoveryMDSecRwRtStHdrstFrwdBkwdPosMax_180_Val: accessed-parameter=KeSMSw4sRecoveryMDSecRwRtStHdrstFrwdBkwdPosMax_180.Val
          PA_KeSMSw4sRecoveryMDSecRwRtStHdrstFrwdBkwdPosMax_Below160_Val: accessed-parameter=KeSMSw4sRecoveryMDSecRwRtStHdrstFrwdBkwdPosMax_Below160.Val
          PA_KeSMSw4sRecoveryMDSecRwRtStHdrstFrwdBkwdPosMax_Over180_Val: accessed-parameter=KeSMSw4sRecoveryMDSecRwRtStHdrstFrwdBkwdPosMax_Over180.Val
          PA_KeSMSw4sRecoveryMDSecRwRtStHdrstFrwdBkwdPosMin_160_Val: accessed-parameter=KeSMSw4sRecoveryMDSecRwRtStHdrstFrwdBkwdPosMin_160.Val
          PA_KeSMSw4sRecoveryMDSecRwRtStHdrstFrwdBkwdPosMin_165_Val: accessed-parameter=KeSMSw4sRecoveryMDSecRwRtStHdrstFrwdBkwdPosMin_165.Val
          PA_KeSMSw4sRecoveryMDSecRwRtStHdrstFrwdBkwdPosMin_170_Val: accessed-parameter=KeSMSw4sRecoveryMDSecRwRtStHdrstFrwdBkwdPosMin_170.Val
          PA_KeSMSw4sRecoveryMDSecRwRtStHdrstFrwdBkwdPosMin_175_Val: accessed-parameter=KeSMSw4sRecoveryMDSecRwRtStHdrstFrwdBkwdPosMin_175.Val
          PA_KeSMSw4sRecoveryMDSecRwRtStHdrstFrwdBkwdPosMin_180_Val: accessed-parameter=KeSMSw4sRecoveryMDSecRwRtStHdrstFrwdBkwdPosMin_180.Val
          PA_KeSMSw4sRecoveryMDSecRwRtStHdrstFrwdBkwdPosMin_Below160_Val: accessed-parameter=KeSMSw4sRecoveryMDSecRwRtStHdrstFrwdBkwdPosMin_Below160.Val
          PA_KeSMSw4sRecoveryMDSecRwRtStHdrstFrwdBkwdPosMin_Over180_Val: accessed-parameter=KeSMSw4sRecoveryMDSecRwRtStHdrstFrwdBkwdPosMin_Over180.Val
          PA_KeSMSw4sVIPMDSecRwRtStHdrstFrwdBkwdPos_160_Val: accessed-parameter=KeSMSw4sVIPMDSecRwRtStHdrstFrwdBkwdPos_160.Val
          PA_KeSMSw4sVIPMDSecRwRtStHdrstFrwdBkwdPos_165_Val: accessed-parameter=KeSMSw4sVIPMDSecRwRtStHdrstFrwdBkwdPos_165.Val
          PA_KeSMSw4sVIPMDSecRwRtStHdrstFrwdBkwdPos_170_Val: accessed-parameter=KeSMSw4sVIPMDSecRwRtStHdrstFrwdBkwdPos_170.Val
          PA_KeSMSw4sVIPMDSecRwRtStHdrstFrwdBkwdPos_175_Val: accessed-parameter=KeSMSw4sVIPMDSecRwRtStHdrstFrwdBkwdPos_175.Val
          PA_KeSMSw4sVIPMDSecRwRtStHdrstFrwdBkwdPos_180_Val: accessed-parameter=KeSMSw4sVIPMDSecRwRtStHdrstFrwdBkwdPos_180.Val
          PA_KeSMSw4sVIPMDSecRwRtStHdrstFrwdBkwdPos_Below160_Val: accessed-parameter=KeSMSw4sVIPMDSecRwRtStHdrstFrwdBkwdPos_Below160.Val
          PA_KeSMSw4sVIPMDSecRwRtStHdrstFrwdBkwdPos_Over180_Val: accessed-parameter=KeSMSw4sVIPMDSecRwRtStHdrstFrwdBkwdPos_Over180.Val
          PA_KeSMSw4sVIPMDSecRwRtStHdrstFrwdBkwdPosMax_160_Val: accessed-parameter=KeSMSw4sVIPMDSecRwRtStHdrstFrwdBkwdPosMax_160.Val
          PA_KeSMSw4sVIPMDSecRwRtStHdrstFrwdBkwdPosMax_165_Val: accessed-parameter=KeSMSw4sVIPMDSecRwRtStHdrstFrwdBkwdPosMax_165.Val
          PA_KeSMSw4sVIPMDSecRwRtStHdrstFrwdBkwdPosMax_170_Val: accessed-parameter=KeSMSw4sVIPMDSecRwRtStHdrstFrwdBkwdPosMax_170.Val
          PA_KeSMSw4sVIPMDSecRwRtStHdrstFrwdBkwdPosMax_175_Val: accessed-parameter=KeSMSw4sVIPMDSecRwRtStHdrstFrwdBkwdPosMax_175.Val
          PA_KeSMSw4sVIPMDSecRwRtStHdrstFrwdBkwdPosMax_180_Val: accessed-parameter=KeSMSw4sVIPMDSecRwRtStHdrstFrwdBkwdPosMax_180.Val
          PA_KeSMSw4sVIPMDSecRwRtStHdrstFrwdBkwdPosMax_Below160_Val: accessed-parameter=KeSMSw4sVIPMDSecRwRtStHdrstFrwdBkwdPosMax_Below160.Val
          PA_KeSMSw4sVIPMDSecRwRtStHdrstFrwdBkwdPosMax_Over180_Val: accessed-parameter=KeSMSw4sVIPMDSecRwRtStHdrstFrwdBkwdPosMax_Over180.Val
          PA_KeSMSw4sVIPMDSecRwRtStHdrstFrwdBkwdPosMin_160_Val: accessed-parameter=KeSMSw4sVIPMDSecRwRtStHdrstFrwdBkwdPosMin_160.Val
          PA_KeSMSw4sVIPMDSecRwRtStHdrstFrwdBkwdPosMin_165_Val: accessed-parameter=KeSMSw4sVIPMDSecRwRtStHdrstFrwdBkwdPosMin_165.Val
          PA_KeSMSw4sVIPMDSecRwRtStHdrstFrwdBkwdPosMin_170_Val: accessed-parameter=KeSMSw4sVIPMDSecRwRtStHdrstFrwdBkwdPosMin_170.Val
          PA_KeSMSw4sVIPMDSecRwRtStHdrstFrwdBkwdPosMin_175_Val: accessed-parameter=KeSMSw4sVIPMDSecRwRtStHdrstFrwdBkwdPosMin_175.Val
          PA_KeSMSw4sVIPMDSecRwRtStHdrstFrwdBkwdPosMin_180_Val: accessed-parameter=KeSMSw4sVIPMDSecRwRtStHdrstFrwdBkwdPosMin_180.Val
          PA_KeSMSw4sVIPMDSecRwRtStHdrstFrwdBkwdPosMin_Below160_Val: accessed-parameter=KeSMSw4sVIPMDSecRwRtStHdrstFrwdBkwdPosMin_Below160.Val
          PA_KeSMSw4sVIPMDSecRwRtStHdrstFrwdBkwdPosMin_Over180_Val: accessed-parameter=KeSMSw4sVIPMDSecRwRtStHdrstFrwdBkwdPosMin_Over180.Val
  swc implementation SecRwRtStHdrstFwdBkwdTrgtPosSelc_Implementation: behavior=SecRwRtStHdrstFwdBkwdTrgtPosSelc_InternalBehavior
    code-descriptors:
      code Default: artifact-descriptors=autosar-engineering-object={short-label=Default, category=SWSRC}
package /PATAC/MSM/ModeAdjust/CalPortInterface
  13 x parameter interface:
    KeSMSw4SAcsMd23SecRwRtStHdrstFrwdBkwdPos
      parameter data prototype Val: sw-calibration-access=READ-WRITE, type=UInt16
    KeSMSw4SAcsMd23SecRwRtStHdrstFrwdBkwdPosMax
      parameter data prototype Val: sw-calibration-access=READ-WRITE, type=UInt16
    KeSMSw4SAcsMd23SecRwRtStHdrstFrwdBkwdPosMin
      parameter data prototype Val: sw-calibration-access=READ-WRITE, type=UInt16
    KeSMSw4SAcsMd24SecRwRtStHdrstFrwdBkwdPos
      parameter data prototype Val: sw-calibration-access=READ-WRITE, type=UInt16
    KeSMSw4SAcsMd24SecRwRtStHdrstFrwdBkwdPosMax
      parameter data prototype Val: sw-calibration-access=READ-WRITE, type=UInt16
    KeSMSw4SAcsMd24SecRwRtStHdrstFrwdBkwdPosMin
      parameter data prototype Val: sw-calibration-access=READ-WRITE, type=UInt16
    KeSMSw4SAcsMd25SecRwRtStHdrstFrwdBkwdPos
      parameter data prototype Val: sw-calibration-access=READ-WRITE, type=UInt16
    KeSMSw4SAcsMd25SecRwRtStHdrstFrwdBkwdPosMax
      parameter data prototype Val: sw-calibration-access=READ-WRITE, type=UInt16
    KeSMSw4SAcsMd25SecRwRtStHdrstFrwdBkwdPosMin
      parameter data prototype Val: sw-calibration-access=READ-WRITE, type=UInt16
    KeSMSw4SAcsMd26SecRwRtStHdrstFrwdBkwdPos
      parameter data prototype Val: sw-calibration-access=READ-WRITE, type=UInt16
    KeSMSw4SAcsMd26SecRwRtStHdrstFrwdBkwdPosMax
      parameter data prototype Val: sw-calibration-access=READ-WRITE, type=UInt16
    KeSMSw4SAcsMd26SecRwRtStHdrstFrwdBkwdPosMin
      parameter data prototype Val: sw-calibration-access=READ-WRITE, type=UInt16
    Pos
      parameter data prototype Val: sw-calibration-access=READ-WRITE, type=UInt16
package /PATAC/MSM/ModeAdjust/DataType
  impl type TrgtPosCalibArray: category=ARRAY, sw-calibration-access=READ-ONLY, type-emitter=RTE  # 0:pos 1:max 2:min
    element Element: array-size=3, array-size-semantics=FIXED-SIZE, implementation-data-type=UInt16, invalid-value=0
package /PATAC/MSM/ModeAdjust/PortInterface
  client server interface SecRwRtStHdrstFwdBkwdTrgtPosSelc
    operation Cal
  sender receiver interface HeightIndex: invalidation-policy{data-element=Val, handle-invalid=DONT-INVALIDATE}
    data Val: type=UInt8  # 0：under 160 1：160 2：165 3：170 4：175 5：180 6：over 180
  sender receiver interface StNumFlg
    4 x data, all with type=Boolean:
      Is4s
      Is6s
      Is6s7s
      Is7s
    invalidation-policys:
      data-element=Is7s, handle-invalid=DONT-INVALIDATE
      data-element=Is6s, handle-invalid=DONT-INVALIDATE
      data-element=Is4s, handle-invalid=DONT-INVALIDATE
      data-element=Is6s7s, handle-invalid=DONT-INVALIDATE
  sender receiver interface TrgtPosCalibArray: invalidation-policy{data-element=TrgtPosArray, handle-invalid=DONT-INVALIDATE}
    data TrgtPosArray: type=TrgtPosCalibArray  # 0:Pos 1:Max 2:Min
